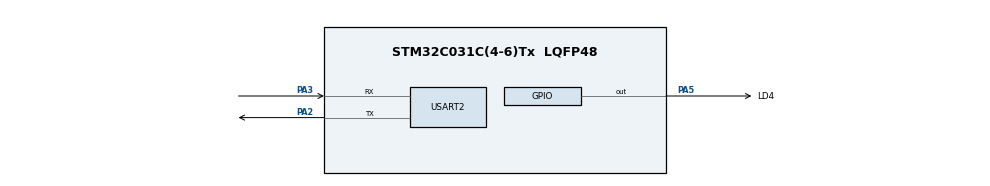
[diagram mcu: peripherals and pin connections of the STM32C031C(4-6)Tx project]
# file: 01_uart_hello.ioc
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Mcu.Family=STM32C0
Mcu.Name=STM32C031C(4-6)Tx
Mcu.Package=LQFP48
NVIC.USART2_IRQn=true\:0\:0\:false\:false\:true\:true\:true\:true
PA13.Mode=Serial_Wire
PA13.Signal=DEBUG_SWDIO
PA14-BOOT0.Mode=Serial_Wire
PA14-BOOT0.Signal=DEBUG_SWCLK
PA2.Mode=Asynchronous
PA2.Signal=USART2_TX
PA3.Mode=Asynchronous
PA3.Signal=USART2_RX
PA5.GPIO_Label=LD4
PA5.Signal=GPIO_Output
ProjectManager.HeapSize=0x200
ProjectManager.StackSize=0x400
ProjectManager.TargetToolchain=STM32CubeIDE
RCC.ADCFreq_Value=12000000
RCC.AHBFreq_Value=12000000
RCC.CortexFreq_Value=12000000
RCC.EXTERNAL_CLOCK_VALUE=12288000
RCC.HCLKFreq_Value=12000000
RCC.HSE_VALUE=8000000
RCC.HSI_VALUE=48000000
RCC.LSE_VALUE=32768
RCC.SYSCLKFreq_VALUE=12000000
USART2.VirtualMode-Asynchronous=VM_ASYNC
board=custom

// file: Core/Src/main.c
/* USER CODE BEGIN Header */
/**
 ******************************************************************************
 * @file           : main.c
 * @brief          : Main program body
 ******************************************************************************
 * @attention
 *
 * Copyright (c) 2026 STMicroelectronics.
 * All rights reserved.
 *
 * This software is licensed under terms that can be found in the LICENSE file
 * in the root directory of this software component.
 * If no LICENSE file comes with this software, it is provided AS-IS.
 *
 ******************************************************************************
 */
/* USER CODE END Header */
#include "main.h"

/* USER CODE BEGIN Includes */
#include <stdio.h>    // snprintf: 숫자를 글자로 바꿔 문장 만들기
/* USER CODE END Includes */

UART_HandleTypeDef huart2;

/* USER CODE BEGIN PV */
uint32_t hello_count = 0;
uint8_t rx_byte;                 // 받은 글자가 들어올 상자 (HAL이 채워 줌)
volatile uint8_t rx_flag = 0;     // "글자 왔다!" 깃발
volatile uint8_t last_char = 0;   // 마지막으로 받은 글자
/* USER CODE END PV */

void SystemClock_Config(void);
static void MX_GPIO_Init(void);
static void MX_USART2_UART_Init(void);

/* USER CODE BEGIN 0 */
int __io_putchar(int ch)                         // printf가 글자 하나를 보낼 때마다 부르는 함수
{
	HAL_UART_Transmit(&huart2, (uint8_t*) &ch, 1, HAL_MAX_DELAY); // 그 글자를 UART로 보내기
	return ch;
}
/* USER CODE END 0 */

int main(void) {

	/* MCU Configuration--------------------------------------------------------*/

	/* Reset of all peripherals, Initializes the Flash interface and the Systick. */
	HAL_Init();

	/* Configure the system clock */
	SystemClock_Config();

	/* Initialize all configured peripherals */
	MX_GPIO_Init();
	MX_USART2_UART_Init();
	/* USER CODE BEGIN 2 */
	setvbuf(stdout, NULL, _IONBF, 0);
	HAL_UART_Receive_IT(&huart2, &rx_byte, 1);   // "글자 1개 오면 초인종 울려 줘" 🔔
	uint32_t last_hello = HAL_GetTick();
	/* USER CODE END 2 */

	/* Infinite loop */
	while (1) {

		/* USER CODE BEGIN 3 */
		if (rx_flag) {                               // 깃발이 섰으면 main에서 처리
			rx_flag = 0;
			printf("받은 글자: %c\r\n", last_char);
		}

		if (HAL_GetTick() - last_hello >= 1000) {    // 1초마다 인사 (HAL_Delay 없이!)
			last_hello = HAL_GetTick();
			printf("Hello %lu\r\n", hello_count++);
		}
	}
	/* USER CODE END 3 */
}

void SystemClock_Config(void) {
	RCC_OscInitTypeDef RCC_OscInitStruct = { 0 };
	RCC_ClkInitTypeDef RCC_ClkInitStruct = { 0 };

	__HAL_FLASH_SET_LATENCY(FLASH_LATENCY_0);

	/** Initializes the RCC Oscillators according to the specified parameters
	 * in the RCC_OscInitTypeDef structure.
	 */
	RCC_OscInitStruct.OscillatorType = RCC_OSCILLATORTYPE_HSI;
	RCC_OscInitStruct.HSIState = RCC_HSI_ON;
	RCC_OscInitStruct.HSIDiv = RCC_HSI_DIV4;
	RCC_OscInitStruct.HSICalibrationValue = RCC_HSICALIBRATION_DEFAULT;
	if (HAL_RCC_OscConfig(&RCC_OscInitStruct) != HAL_OK) {
		Error_Handler();
	}

	/** Initializes the CPU, AHB and APB buses clocks
	 */
	RCC_ClkInitStruct.ClockType = RCC_CLOCKTYPE_HCLK | RCC_CLOCKTYPE_SYSCLK
			| RCC_CLOCKTYPE_PCLK1;
	RCC_ClkInitStruct.SYSCLKSource = RCC_SYSCLKSOURCE_HSI;
	RCC_ClkInitStruct.SYSCLKDivider = RCC_SYSCLK_DIV1;
	RCC_ClkInitStruct.AHBCLKDivider = RCC_HCLK_DIV1;
	RCC_ClkInitStruct.APB1CLKDivider = RCC_APB1_DIV1;

	if (HAL_RCC_ClockConfig(&RCC_ClkInitStruct, FLASH_LATENCY_0) != HAL_OK) {
		Error_Handler();
	}
}

static void MX_USART2_UART_Init(void) {

	huart2.Instance = USART2;
	huart2.Init.BaudRate = 115200;
	huart2.Init.WordLength = UART_WORDLENGTH_8B;
	huart2.Init.StopBits = UART_STOPBITS_1;
	huart2.Init.Parity = UART_PARITY_NONE;
	huart2.Init.Mode = UART_MODE_TX_RX;
	huart2.Init.HwFlowCtl = UART_HWCONTROL_NONE;
	huart2.Init.OverSampling = UART_OVERSAMPLING_16;
	huart2.Init.OneBitSampling = UART_ONE_BIT_SAMPLE_DISABLE;
	huart2.Init.ClockPrescaler = UART_PRESCALER_DIV1;
	huart2.AdvancedInit.AdvFeatureInit = UART_ADVFEATURE_NO_INIT;
	if (HAL_UART_Init(&huart2) != HAL_OK) {
		Error_Handler();
	}

}

static void MX_GPIO_Init(void) {
	GPIO_InitTypeDef GPIO_InitStruct = { 0 };

	/* GPIO Ports Clock Enable */
	__HAL_RCC_GPIOA_CLK_ENABLE();

	/*Configure GPIO pin Output Level */
	HAL_GPIO_WritePin(LD4_GPIO_Port, LD4_Pin, GPIO_PIN_RESET);

	/*Configure GPIO pin : LD4_Pin */
	GPIO_InitStruct.Pin = LD4_Pin;
	GPIO_InitStruct.Mode = GPIO_MODE_OUTPUT_PP;
	GPIO_InitStruct.Pull = GPIO_NOPULL;
	GPIO_InitStruct.Speed = GPIO_SPEED_FREQ_LOW;
	HAL_GPIO_Init(LD4_GPIO_Port, &GPIO_InitStruct);

}

/* USER CODE BEGIN 4 */
void HAL_UART_RxCpltCallback(UART_HandleTypeDef *huart) {
	if (huart->Instance == USART2) {
		if (rx_byte == '1')
			HAL_GPIO_WritePin(LD4_GPIO_Port, LD4_Pin, GPIO_PIN_SET);   // 1 → 켜기
		if (rx_byte == '0')
			HAL_GPIO_WritePin(LD4_GPIO_Port, LD4_Pin, GPIO_PIN_RESET); // 0 → 끄기
		last_char = rx_byte;
		rx_flag = 1;                                   // 깃발만 세우고
//		HAL_UART_Receive_IT(&huart2, &rx_byte, 1);     // 다음 글자 받을 준비 (다시 걸기!)
	}
}
/* USER CODE END 4 */

void Error_Handler(void) {
	__disable_irq();
	while (1) {
	}
}
